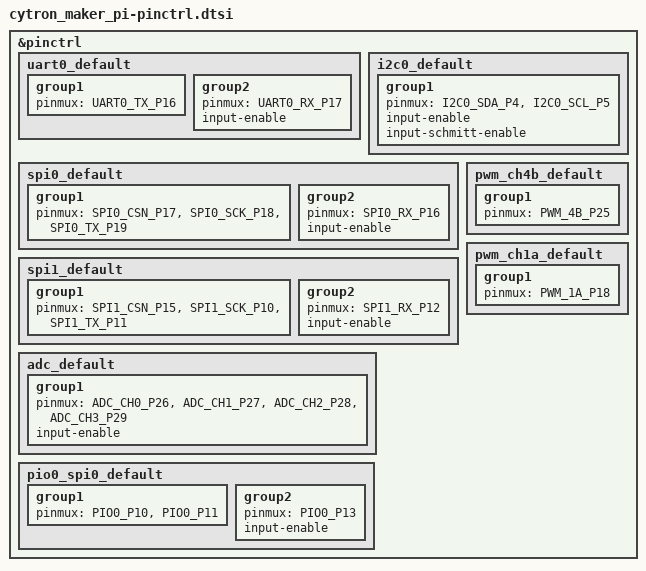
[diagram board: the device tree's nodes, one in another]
/*
 * Copyright (c) 2021, Yonatan Schachter
 * SPDX-License-Identifier: Apache-2.0
 */

#include <zephyr/dt-bindings/pinctrl/rpi-pico-rp2040-pinctrl.h>

&pinctrl {
	uart0_default: uart0_default {
		group1 {
			pinmux = <UART0_TX_P16>;
		};
		group2 {
			pinmux = <UART0_RX_P17>;
			input-enable;
		};
	};

	i2c0_default: i2c0_default {
		group1 {
			pinmux = <I2C0_SDA_P4>, <I2C0_SCL_P5>;
			input-enable;
			input-schmitt-enable;
		};
	};

	spi0_default: spi0_default {
		group1 {
			pinmux = <SPI0_CSN_P17>, <SPI0_SCK_P18>, <SPI0_TX_P19>;
		};
		group2 {
			pinmux = <SPI0_RX_P16>;
			input-enable;
		};
	};

	spi1_default: spi1_default {
		group1 {
			pinmux = <SPI1_CSN_P15>, <SPI1_SCK_P10>, <SPI1_TX_P11>;
		};
		group2 {
			pinmux = <SPI1_RX_P12>;
			input-enable;
		};
	};

	pwm_ch4b_default: pwm_ch4b_default {
		group1 {
			pinmux = <PWM_4B_P25>;
		};
	};

	pwm_ch1a_default: pwm_ch1a_default {
		group1 {
			pinmux = <PWM_1A_P18>;
		};
	};

	adc_default: adc_default {
		group1 {
			pinmux = <ADC_CH0_P26>, <ADC_CH1_P27>, <ADC_CH2_P28>, <ADC_CH3_P29>;
			input-enable;
		};
	};

	pio0_spi0_default: pio0_spi0_default {
		/* gpio 13 is used for chip select, not assigned to the PIO */
		group1 {
			pinmux = <PIO0_P10>, <PIO0_P11>;
		};
		group2 {
			pinmux = <PIO0_P13>;
			input-enable;
		};
	};
};
